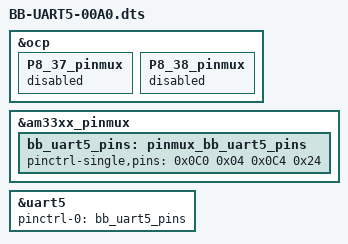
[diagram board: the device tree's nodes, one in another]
/*
 * Copyright (C) 2024 Colorado State University
 * 
 * This program is free software; you can redistribute it and/or modify
 * it under the terms of the GNU General Public License version 2 as
 * published by the Free Software Foundation.
 */

/dts-v1/;
/plugin/;

/ {

        /*
         * Free up the pins used by the cape from the pinmux helpers.
         */
        fragment@0 {
                target = <&ocp>;
                __overlay__ {
                        P8_37_pinmux { status = "disabled"; };  /* uart5_txd */
                        P8_38_pinmux { status = "disabled"; };  /* uart5_rxd */
                };
        };

        fragment@1 {
                target = <&am33xx_pinmux>;
                __overlay__ {
                        bb_uart5_pins: pinmux_bb_uart5_pins {
                                pinctrl-single,pins = <
                                        0x0C0 0x04      // lcd_data8.uart5_txd, PIN_OUTPUT (PULL_DISABLE | MUX_MODE4)
                                        0x0C4 0x24      // lcd_data9.uart5_rxd, PIN_INPUT (INPUT_EN | PULL_DISABLE | MUX_MODE4)
                                >;
                        };
                };
        };

        fragment@2 {
                target = <&uart5>;
                __overlay__ {
                        status = "okay";
                        pinctrl-names = "default";
                        pinctrl-0 = <&bb_uart5_pins>;
                };
        };
};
